AUTOSAR XML (schema 4.0)
package /FV/If
  23 x sender receiver interface:
    MediaReq
      data payload
    MediaStream
      data stream
    NavRoute
      data route
    RemoteSvc
      data val
    OtaCmd
      data pkg
    V2xMsg
      data msg
    DiagCmd
      data cmd
    FwPolicy
      data rule
    ComfortMode
      data mode
    ObjData
      data objects
    LaneData
      data lanes
    DecelReq
      data decel
    BrakeForce
      data force
    SteerAngle
      data angle
    EngineCmd
      data torque
    TransGear
      data gear
    EmisData
      data emis
    BodyCmd
      data cmd
    DoorCmd
      data lock
    HvacCmd
      data temp
    LightCmd
      data level
    TailCmd
      data level
    AmbientCmd
      data color
package /FV/Swc
  application sw component type BluetoothStack
    provide port MediaOut: provided-interface=MediaReq
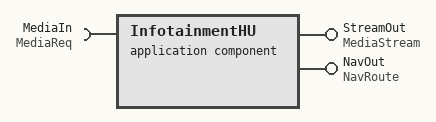
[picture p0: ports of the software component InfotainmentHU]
  application sw component type InfotainmentHU
    require port MediaIn: required-interface=MediaReq
    provide port StreamOut: provided-interface=MediaStream
    provide port NavOut: provided-interface=NavRoute
  application sw component type MediaPlayer
    require port StreamIn: required-interface=MediaStream
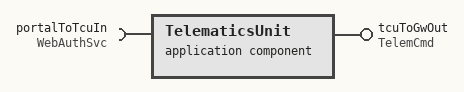
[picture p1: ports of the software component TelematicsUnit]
  application sw component type TelematicsUnit
    provide port RemoteOut: provided-interface=RemoteSvc
  application sw component type OtaManager
    provide port OtaOut: provided-interface=OtaCmd
  application sw component type V2xStack
    provide port V2xOut: provided-interface=V2xMsg
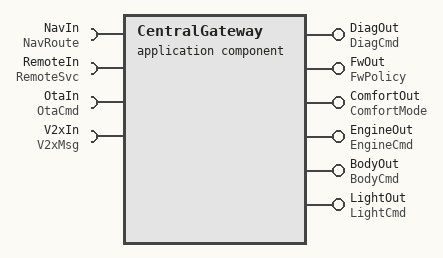
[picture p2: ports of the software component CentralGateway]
  application sw component type CentralGateway
    4 x require port:
      NavIn: required-interface=NavRoute
      RemoteIn: required-interface=RemoteSvc
      OtaIn: required-interface=OtaCmd
      V2xIn: required-interface=V2xMsg
    6 x provide port:
      DiagOut: provided-interface=DiagCmd
      FwOut: provided-interface=FwPolicy
      ComfortOut: provided-interface=ComfortMode
      EngineOut: provided-interface=EngineCmd
      BodyOut: provided-interface=BodyCmd
      LightOut: provided-interface=LightCmd
  application sw component type DiagnosticRouter
    require port DiagIn: required-interface=DiagCmd
  application sw component type FirewallManager
    require port FwIn: required-interface=FwPolicy
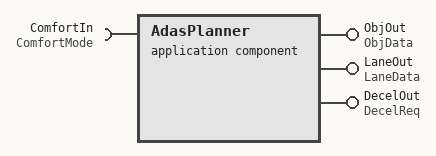
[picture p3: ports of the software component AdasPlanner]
  application sw component type AdasPlanner
    require port ComfortIn: required-interface=ComfortMode
    provide port ObjOut: provided-interface=ObjData
    provide port LaneOut: provided-interface=LaneData
    provide port DecelOut: provided-interface=DecelReq
  application sw component type ObjectDetector
    require port ObjIn: required-interface=ObjData
  application sw component type LaneKeepAssist
    require port LaneIn: required-interface=LaneData
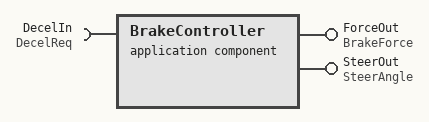
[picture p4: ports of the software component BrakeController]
  application sw component type BrakeController
    require port DecelIn: required-interface=DecelReq
    provide port ForceOut: provided-interface=BrakeForce
    provide port SteerOut: provided-interface=SteerAngle
  sensor actuator sw component type BrakeActuator
    require port ForceIn: required-interface=BrakeForce
  sensor actuator sw component type SteeringController
    require port SteerIn: required-interface=SteerAngle
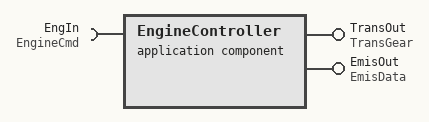
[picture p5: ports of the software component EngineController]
  application sw component type EngineController
    require port EngIn: required-interface=EngineCmd
    provide port TransOut: provided-interface=TransGear
    provide port EmisOut: provided-interface=EmisData
  application sw component type TransmissionCtrl
    require port TransIn: required-interface=TransGear
  application sw component type EmissionsCtrl
    require port EmisIn: required-interface=EmisData
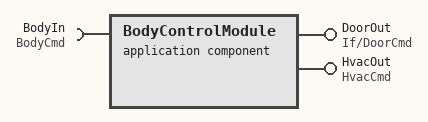
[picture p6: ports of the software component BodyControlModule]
  application sw component type BodyControlModule
    require port BodyIn: required-interface=BodyCmd
    provide port DoorOut: provided-interface=If/DoorCmd
    provide port HvacOut: provided-interface=HvacCmd
  sensor actuator sw component type DoorLockActuator
    require port DoorIn: required-interface=If/DoorCmd
  application sw component type HvacController
    require port HvacIn: required-interface=HvacCmd
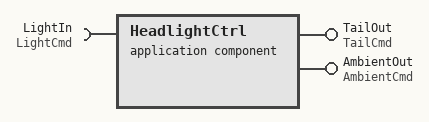
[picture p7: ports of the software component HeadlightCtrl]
  application sw component type HeadlightCtrl
    require port LightIn: required-interface=LightCmd
    provide port TailOut: provided-interface=TailCmd
    provide port AmbientOut: provided-interface=AmbientCmd
  sensor actuator sw component type TaillightCtrl
    require port TailIn: required-interface=TailCmd
  application sw component type AmbientLightCtrl
    require port AmbientIn: required-interface=AmbientCmd
  composition sw component type FullVehicle
    24 x component:
      btStack: type=BluetoothStack
      ivi: type=InfotainmentHU
      mediaPlayer: type=MediaPlayer
      tcu: type=Swc/TelematicsUnit
      otaManager: type=OtaManager
      v2xStack: type=V2xStack
      cgw: type=CentralGateway
      diagRouter: type=DiagnosticRouter
      firewallMgr: type=FirewallManager
      adas: type=AdasPlanner
      objDetect: type=ObjectDetector
      laneKeep: type=LaneKeepAssist
      brakeCtl: type=BrakeController
      brakeAct: type=BrakeActuator
      steerCtl: type=SteeringController
      engineCtl: type=EngineController
      transCtl: type=TransmissionCtrl
      emisCtl: type=EmissionsCtrl
      bcm: type=BodyControlModule
      doorLock: type=DoorLockActuator
      hvacCtl: type=HvacController
      headlight: type=HeadlightCtrl
      taillight: type=TaillightCtrl
      ambientLight: type=AmbientLightCtrl
    connect btStack.MediaOut -> ivi.MediaIn
    connect ivi.StreamOut -> mediaPlayer.StreamIn
    connect ivi.NavOut -> cgw.NavIn
    connect tcu.RemoteOut -> cgw.RemoteIn
    connect otaManager.OtaOut -> cgw.OtaIn
    connect v2xStack.V2xOut -> cgw.V2xIn
    connect cgw.DiagOut -> diagRouter.DiagIn
    connect cgw.FwOut -> firewallMgr.FwIn
    connect adas.DecelOut -> brakeCtl.DecelIn
    connect adas.ObjOut -> objDetect.ObjIn
    connect adas.LaneOut -> laneKeep.LaneIn
    connect brakeCtl.ForceOut -> brakeAct.ForceIn
    connect brakeCtl.SteerOut -> steerCtl.SteerIn
    connect cgw.EngineOut -> engineCtl.EngIn
    connect engineCtl.TransOut -> transCtl.TransIn
    connect engineCtl.EmisOut -> emisCtl.EmisIn
    connect cgw.BodyOut -> bcm.BodyIn
    connect bcm.DoorOut -> doorLock.DoorIn
    connect bcm.HvacOut -> hvacCtl.HvacIn
    connect cgw.LightOut -> headlight.LightIn
    connect headlight.TailOut -> taillight.TailIn
    connect headlight.AmbientOut -> ambientLight.AmbientIn
package /FV/Comm
  pdu NavIPdu
    signal NavISig: system signal NavSSig
  secured i pdu NavSecuredIPdu: auth-info-tx-length=32, freshness-value-id=1, freshness-value-length=8, payload=NavIPdu
  pdu TcuGwIPdu
    signal TcuGwISig: system signal TcuGwSSig
  secured i pdu TcuGwSecuredIPdu: auth-info-tx-length=32, freshness-value-id=2, freshness-value-length=8, payload=TcuGwIPdu
  pdu OtaIPdu
    signal OtaISig: system signal OtaSSig
  pdu V2xIPdu
    signal V2xISig: system signal V2xSSig
  secured i pdu V2xSecuredIPdu: auth-info-tx-length=32, freshness-value-id=3, freshness-value-length=8, payload=V2xIPdu
  pdu ComfortIPdu
    signal ComfortISig: system signal ComfortSSig
  pdu DecelIPdu
    signal DecelISig: system signal DecelSSig
  secured i pdu DecelSecuredIPdu: auth-info-tx-length=32, freshness-value-id=4, freshness-value-length=8, payload=DecelIPdu
  pdu EngineIPdu
    signal EngineISig: system signal EngineSSig
  secured i pdu EngineSecuredIPdu: auth-info-tx-length=32, freshness-value-id=5, freshness-value-length=8, payload=EngineIPdu
  pdu BodyIPdu
    signal BodyISig: system signal BodySSig
  pdu LightIPdu
    signal LightISig: system signal LightSSig
package /FV/Topology
  8 x ecu instance:
    IviEcu
    TelematicsEcu
    GatewayEcu
    AdasEcu
    ChassisEcu
    PtEcu
    BodyEcu
    LightEcu
  system FullVeh
    root-software-compositions:
      root sw composition prototype Root: software-composition=FullVehicle
    system mapping Map
      data-mappings:
        data-element=Root.NavOut.route, system-signal=NavSSig
        data-element=Root.RemoteOut.val, system-signal=TcuGwSSig
        data-element=Root.OtaOut.pkg, system-signal=OtaSSig
        data-element=Root.V2xOut.msg, system-signal=V2xSSig
        data-element=Root.ComfortOut.mode, system-signal=ComfortSSig
        data-element=Root.DecelOut.decel, system-signal=DecelSSig
        data-element=Root.EngineOut.torque, system-signal=EngineSSig
        data-element=Root.BodyOut.cmd, system-signal=BodySSig
        data-element=Root.LightOut.level, system-signal=LightSSig
      sw-mappings:
        8 x swc to ecu mapping:
          ToIvi: component=[btStack, ivi, mediaPlayer], ecu-instance=IviEcu
          ToTelematics: component=[tcu, otaManager, v2xStack], ecu-instance=Topology/TelematicsEcu
          ToGateway: component=[cgw, diagRouter, firewallMgr], ecu-instance=Topology/GatewayEcu
          ToAdas: component=[adas, objDetect, laneKeep], ecu-instance=AdasEcu
          ToChassis: component=[brakeCtl, brakeAct, steerCtl], ecu-instance=ChassisEcu
          ToPt: component=[engineCtl, transCtl, emisCtl], ecu-instance=PtEcu
          ToBody: component=[bcm, doorLock, hvacCtl], ecu-instance=Topology/BodyEcu
          ToLight: component=[headlight, taillight, ambientLight], ecu-instance=LightEcu
package /S10API/If
  sender receiver interface WebAuthSvc
    data val
  sender receiver interface TelemCmd
    data val
  sender receiver interface DoorCmd
    data val
package /S10API/Swc
  application sw component type DealerPortalApi
    provide port portalToTcuOut: provided-interface=WebAuthSvc
  application sw component type TelematicsUnit
    provide port tcuToGwOut: provided-interface=TelemCmd
    require port portalToTcuIn: required-interface=WebAuthSvc
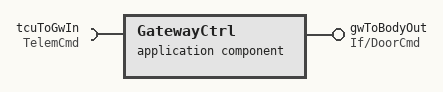
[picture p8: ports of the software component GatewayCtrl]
  application sw component type GatewayCtrl
    provide port gwToBodyOut: provided-interface=If/DoorCmd
    require port tcuToGwIn: required-interface=TelemCmd
  application sw component type BodyDoorControl
    require port gwToBodyIn: required-interface=If/DoorCmd
  composition sw component type Root
    4 x component:
      portal: type=DealerPortalApi
      tcu: type=Swc/TelematicsUnit
      gw: type=GatewayCtrl
      body: type=BodyDoorControl
    connect portal.portalToTcuOut -> tcu.portalToTcuIn
    connect tcu.tcuToGwOut -> gw.tcuToGwIn
    connect gw.gwToBodyOut -> body.gwToBodyIn
package /S10API/Comm
  pdu portalToTcuIPdu
    signal portalToTcuISig: system signal portalToTcuSSig
  secured i pdu portalToTcuSecuredIPdu: auth-info-tx-length=32, freshness-value-id=1, freshness-value-length=8, payload=portalToTcuIPdu
  pdu tcuToGwIPdu
    signal tcuToGwISig: system signal tcuToGwSSig
  secured i pdu tcuToGwSecuredIPdu: auth-info-tx-length=32, freshness-value-id=1, freshness-value-length=8, payload=tcuToGwIPdu
  pdu gwToBodyIPdu
    signal gwToBodyISig: system signal gwToBodySSig
  secured i pdu gwToBodySecuredIPdu: auth-info-tx-length=32, freshness-value-id=1, freshness-value-length=8, payload=gwToBodyIPdu
package /S10API/Topology
  ecu instance BodyEcu
  ecu instance GatewayEcu
  ecu instance TelematicsEcu
  system Veh
    root-software-compositions:
      root sw composition prototype Root: software-composition=Root
    system mapping Map
      data-mappings:
        data-element=Root.portalToTcuOut.val, system-signal=portalToTcuSSig
        data-element=Root.tcuToGwOut.val, system-signal=tcuToGwSSig
        data-element=Root.gwToBodyOut.val, system-signal=gwToBodySSig
      sw-mappings:
        swc to ecu mapping ToBodyEcu: component=body, ecu-instance=Topology/BodyEcu
        swc to ecu mapping ToGatewayEcu: component=gw, ecu-instance=Topology/GatewayEcu
        swc to ecu mapping ToTelematicsEcu: component=[portal, tcu], ecu-instance=Topology/TelematicsEcu
